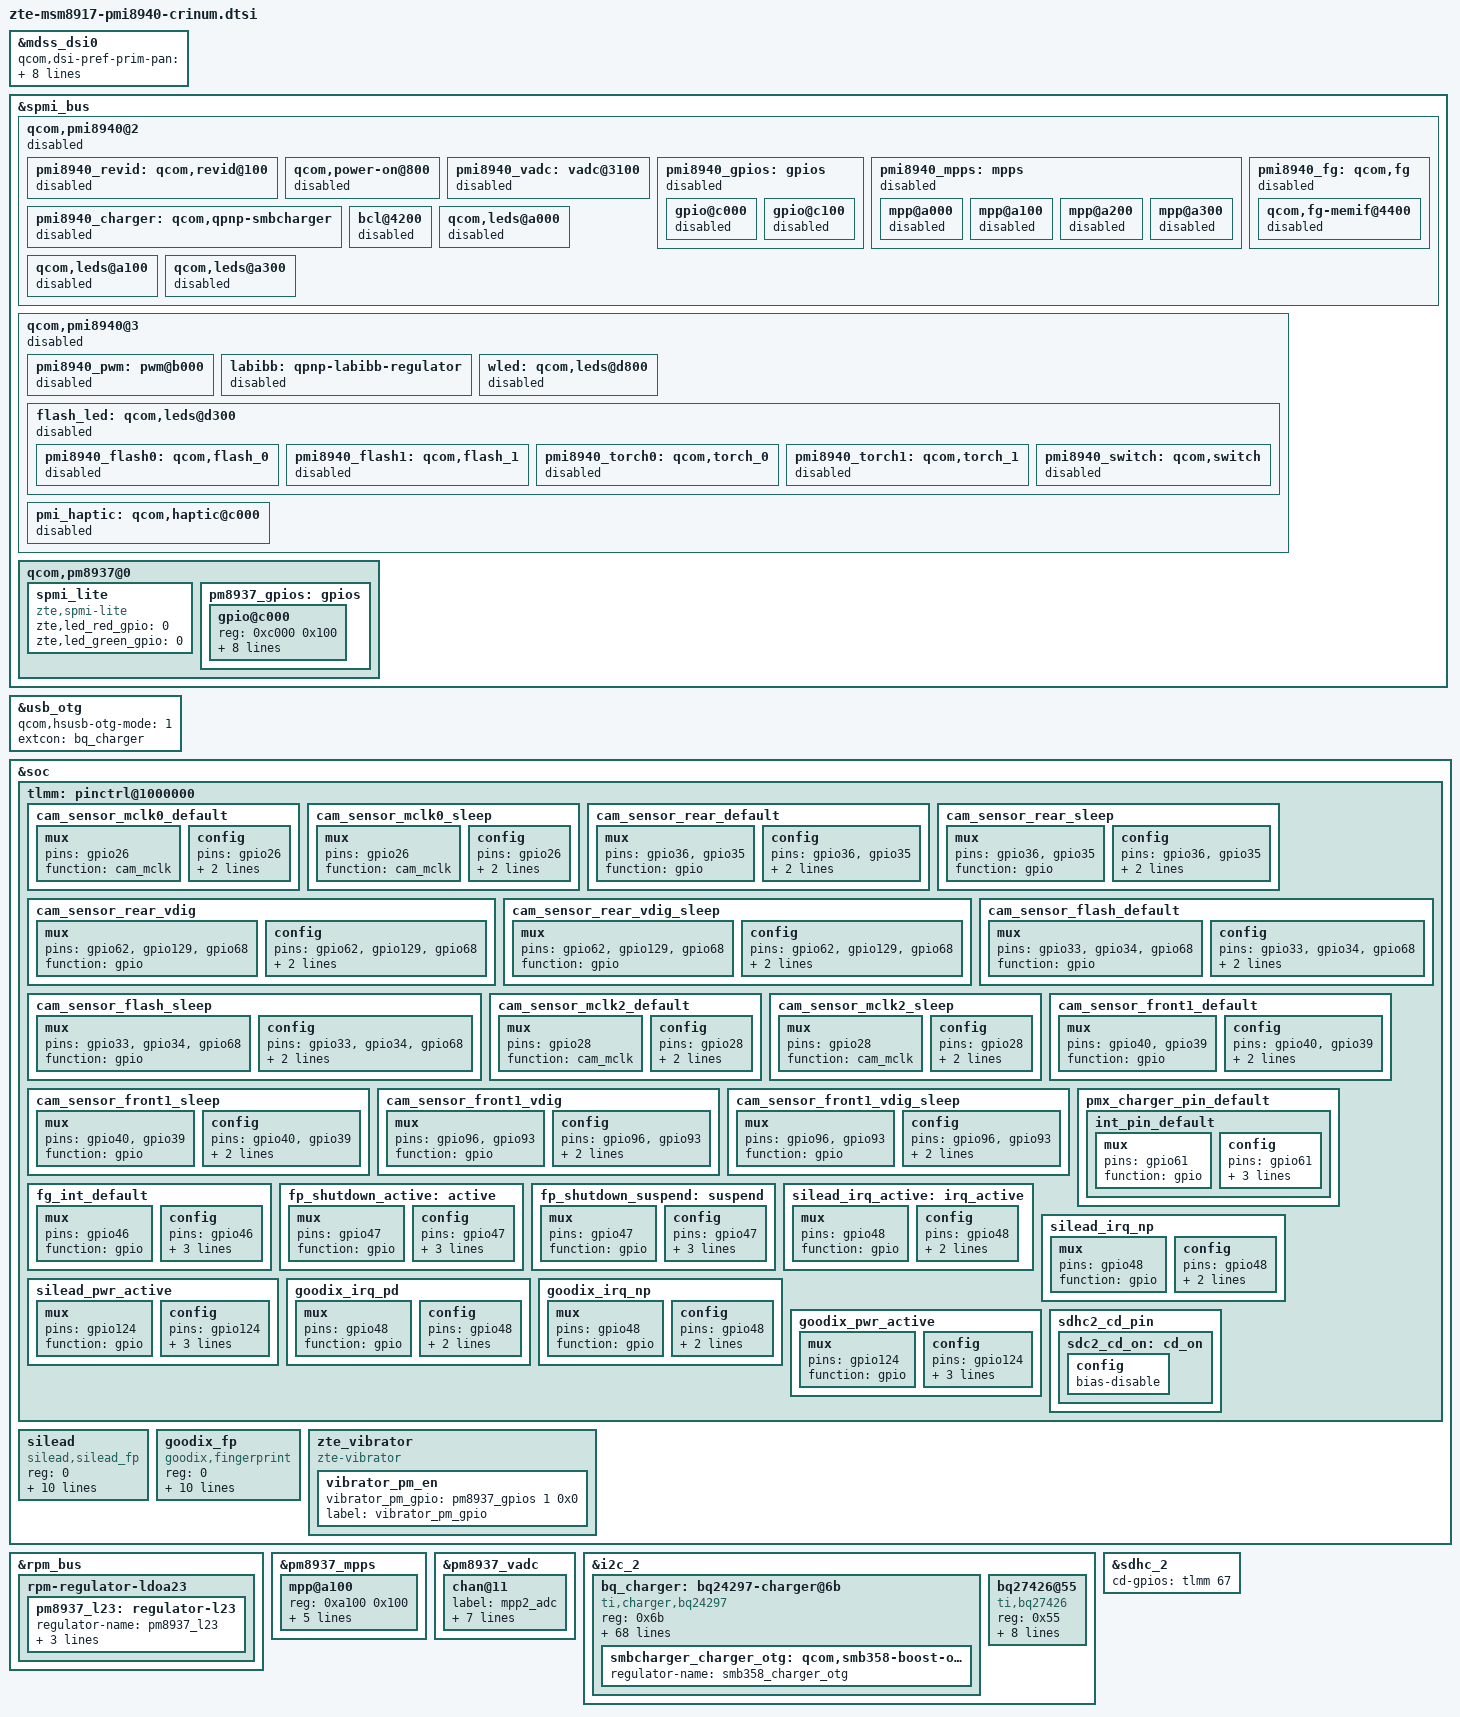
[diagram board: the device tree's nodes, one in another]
/*
 * Copyright (c) 2016, The Linux Foundation. All rights reserved.
 *
 * This program is free software; you can redistribute it and/or modify
 * it under the terms of the GNU General Public License version 2 and
 * only version 2 as published by the Free Software Foundation.
 *
 * This program is distributed in the hope that it will be useful,
 * but WITHOUT ANY WARRANTY; without even the implied warranty of
 * MERCHANTABILITY or FITNESS FOR A PARTICULAR PURPOSE.  See the
 * GNU General Public License for more details.
 */

/*
* device tree for zte crinum board
*/

#include "dsi-panel-zte-truly-otm1290a-cpt-5p5-720p-video.dtsi"
#include "dsi-panel-zte-lianchuang-jd9365d-hsd-720p-video.dtsi"
#include "dsi-panel-zte-helitai-st7703-hsd-5p5-720p-video.dtsi"

&mdss_dsi0 {
	qcom,dsi-pref-prim-pan = <&dsi_truly_otm1290a_cpt_720p_video>;
	pinctrl-names = "mdss_default", "mdss_sleep";
	pinctrl-0 = <&mdss_dsi_active &mdss_te_active>;
	pinctrl-1 = <&mdss_dsi_suspend &mdss_te_suspend>;

	qcom,platform-te-gpio = <&tlmm 24 0>;
	qcom,platform-reset-gpio = <&tlmm 60 0>;

	qcom,regulator-ldo-mode;

	zte,disp_vsp_en_gpio = <&tlmm 89 0>;
	zte,disp_vsn_en_gpio = <&tlmm 90 0>;
};

&spmi_bus {
	qcom,pmi8940@2 {
		status = "disabled";

		pmi8940_revid: qcom,revid@100 {
			status = "disabled";
		};

		qcom,power-on@800 {
			status = "disabled";
		};

		pmi8940_vadc: vadc@3100 {
			status = "disabled";
		};

		pmi8940_gpios: gpios {
			status = "disabled";

			gpio@c000 {
				status = "disabled";
			};

			gpio@c100 {
				status = "disabled";
			};
		};

		pmi8940_mpps: mpps {
			status = "disabled";

			mpp@a000 {
				status = "disabled";
			};

			mpp@a100 {
				status = "disabled";
			};

			mpp@a200 {
				status = "disabled";
			};

			mpp@a300 {
				status = "disabled";
			};
		};

		pmi8940_charger: qcom,qpnp-smbcharger {
			status = "disabled";
		};

		pmi8940_fg: qcom,fg {
			status = "disabled";

			qcom,fg-memif@4400 {
				status = "disabled";
			};
		};

		bcl@4200 {
			status = "disabled";
		};
		qcom,leds@a000 {
			status = "disabled";
		};
		qcom,leds@a100 {
			status = "disabled";
		};
		qcom,leds@a300 {
			status = "disabled";
		};
	};

	qcom,pmi8940@3 {
		status = "disabled";

		pmi8940_pwm: pwm@b000 {
			status = "disabled";
		};

		labibb: qpnp-labibb-regulator {
			status = "disabled";
		};

		wled: qcom,leds@d800 {
			status = "disabled";
		};

		flash_led: qcom,leds@d300 {
			status = "disabled";

			pmi8940_flash0: qcom,flash_0 {
				status = "disabled";
			};

			pmi8940_flash1: qcom,flash_1 {
				status = "disabled";
			};

			pmi8940_torch0: qcom,torch_0 {
				status = "disabled";
			};

			pmi8940_torch1: qcom,torch_1 {
				status = "disabled";
			};

			pmi8940_switch: qcom,switch {
				status = "disabled";
			};
		};

		pmi_haptic: qcom,haptic@c000 {
			status = "disabled";
		};
	};
};

&usb_otg {
	qcom,hsusb-otg-mode = <1>;
	extcon = <&bq_charger>;
};

/*ZTE yuxin add for zte Z5151V crinum prj camera gpios 2017.12.16 begin*/
&soc {
	tlmm: pinctrl@1000000 {
	/*sensors */
		cam_sensor_mclk0_default: cam_sensor_mclk0_default {
			/* MCLK0 */
				mux {
				/* CLK, DATA */
				pins = "gpio26";
				function = "cam_mclk";
			};

			config {
				pins = "gpio26";
				bias-disable; /* No PULL */
				drive-strength = <4>; /* 2 MA */
			};
		};

		cam_sensor_mclk0_sleep: cam_sensor_mclk0_sleep {
			/* MCLK0 */
			mux {
				/* CLK, DATA */
				pins = "gpio26";
				function = "cam_mclk";
			};

			config {
				pins = "gpio26";
				bias-pull-down; /* PULL DOWN */
				drive-strength = <4>; /* 2 MA */
			};
		};

		cam_sensor_rear_default: cam_sensor_rear_default {
			/* RESET, STANDBY */
			mux {
				pins = "gpio36", "gpio35";
				function = "gpio";
			};

			config {
				pins = "gpio36","gpio35";
				bias-disable; /* No PULL */
				drive-strength = <2>; /* 2 MA */
			};
		};

		cam_sensor_rear_sleep: cam_sensor_rear_sleep {
			/* RESET, STANDBY */
			mux {
				pins = "gpio36","gpio35";
				function = "gpio";
			};

			config {
				pins = "gpio36","gpio35";
				bias-disable; /* No PULL */
				drive-strength = <2>; /* 2 MA */
			};
		};

		cam_sensor_rear_vdig: cam_sensor_rear_vdig {
			/* VDIG */
			mux {
				pins = "gpio62","gpio129","gpio68";
				function = "gpio";
			};

			config {
				pins = "gpio62","gpio129","gpio68";
				bias-disable; /* No PULL */
				drive-strength = <2>; /* 2 MA */
			};
		};

		cam_sensor_rear_vdig_sleep: cam_sensor_rear_vdig_sleep {
			/* VDIG */
			mux {
				pins = "gpio62","gpio129","gpio68";
				function = "gpio";
			};

			config {
				pins = "gpio62","gpio129","gpio68";
				bias-disable; /* No PULL */
				drive-strength = <2>; /* 2 MA */
			};
		};
		/*yuxin add for Z5151V flash 20180123 ++*/
		cam_sensor_flash_default: cam_sensor_flash_default {
			/* VDIG */
			mux {
				pins = "gpio33", "gpio34", "gpio68";
				function = "gpio";
			};

			config {
				pins = "gpio33", "gpio34", "gpio68";
				bias-disable; /* No PULL */
				drive-strength = <2>; /* 2 MA */
			};
		};

		cam_sensor_flash_sleep: cam_sensor_flash_sleep {
			/* VDIG */
			mux {
				pins = "gpio33", "gpio34", "gpio68";
				function = "gpio";
			};

			config {
				pins = "gpio33", "gpio34", "gpio68";
				bias-disable; /* No PULL */
				drive-strength = <2>; /* 2 MA */
			};
		};
	/*yuxin add for Z5151V flash 20180123 --*/
		cam_sensor_mclk2_default: cam_sensor_mclk2_default {
			/* MCLK2 */
			mux {
				/* CLK, DATA */
				pins = "gpio28";
				function = "cam_mclk";
			};

			config {
				pins = "gpio28";
				bias-disable; /* No PULL */
				drive-strength = <4>; /* 2 MA */
			};
		};

		cam_sensor_mclk2_sleep: cam_sensor_mclk2_sleep {
			/* MCLK2 */
			mux {
				/* CLK, DATA */
				pins = "gpio28";
				function = "cam_mclk";
			};

			config {
				pins = "gpio28";
				bias-pull-down; /* PULL DOWN */
				drive-strength = <4>; /* 2 MA */
			};
		};

		cam_sensor_front1_default: cam_sensor_front1_default {
			/* RESET, STANDBY */
			mux {
				pins = "gpio40", "gpio39";
				function = "gpio";
			};

			config {
				pins = "gpio40", "gpio39";
				bias-disable; /* No PULL */
				drive-strength = <2>; /* 2 MA */
			};
		};

		cam_sensor_front1_sleep: cam_sensor_front1_sleep {
			/* RESET, STANDBY */
			mux {
				pins = "gpio40", "gpio39";
				function = "gpio";
			};

			config {
				pins = "gpio40", "gpio39";
				bias-disable; /* No PULL */
				drive-strength = <2>; /* 2 MA */
			};
		};
		cam_sensor_front1_vdig: cam_sensor_front1_vdig {
			/* VDIG */
			mux {
				pins = "gpio96", "gpio93"; /*"gpio68" is used for rear cam too*/
				function = "gpio";
			};

			config {
				pins = "gpio96", "gpio93"; /*"gpio68" is used for rear cam too*/
				bias-disable; /* No PULL */
				drive-strength = <2>; /* 2 MA */
			};
		};

		cam_sensor_front1_vdig_sleep: cam_sensor_front1_vdig_sleep {
			/* VDIG */
			mux {
				pins = "gpio96", "gpio93"; /*"gpio68" is used for rear cam too*/
				function = "gpio";
			};

			config {
				pins = "gpio96", "gpio93"; /*"gpio68" is used for rear cam too*/
				bias-disable; /* No PULL */
				drive-strength = <2>; /* 2 MA */
			};
		};

		pmx_charger_pin_default {
			int_pin_default: int_pin_default {
				mux {
					pins = "gpio61";
					function = "gpio";
				};

				config {
					pins = "gpio61";
					drive-strength = <2>;
					bias-disable;
					input-enable;
				};
			};
		};

		fg_int_default: fg_int_default {
			mux {
				pins = "gpio46";
				function = "gpio";
			};

			config {
				pins = "gpio46";
				drive-strength = <2>;
				bias-disable;
				input-enable;
			};
		};
	};
};
/*yuxin modify VREG_L23 voltage range for rear camera DVDD supply 20171222 begin*/
&rpm_bus {
	rpm-regulator-ldoa23 {
		status = "okay";
		pm8937_l23: regulator-l23 {
			regulator-name = "pm8937_l23";
			regulator-min-microvolt = <1050000>;
			regulator-max-microvolt = <1200000>;
			qcom,init-voltage = <1050000>;
			status = "okay";
		};
	};
};
/*yuxin modify VREG_L23 voltage range for rear camera DVDD supply 20171222 end*/

/*ZTE yuxin add for zte Z5151V crinum prj camera gpios 2017.12.16 end*/

&tlmm {
	fp_shutdown_active:active{
		mux{
			pins = "gpio47";
			function = "gpio";
		};
		config{
			pins = "gpio47";
			drive-strength = <6>;
			output-high;
			bias-disable = <0>;
		};
	};

	fp_shutdown_suspend:suspend{
		mux{
			pins = "gpio47";
			function = "gpio";
		};
		config{
			pins = "gpio47";
			drive-strength = <2>;
			output-low;
			bias-disable = <0>;
		};
	};

	silead_irq_active:irq_active{
		mux{
			pins = "gpio48";
			function = "gpio";
		};
		config{
			pins = "gpio48";
			drive-strength = <2>;
			bias-pull-down;
		};
	};
	silead_irq_np:silead_irq_np{
		mux{
			pins = "gpio48";
			function = "gpio";
		};
		config{
			pins = "gpio48";
			drive-strength = <2>;
			bias-disable; /* No PULL */
		};
	};

	silead_pwr_active: silead_pwr_active {
		mux{
			pins = "gpio124";
			function = "gpio";
		};
		config {
			pins = "gpio124";
			drive-strength = <2>;
			bias-disable;
			output-high;
		};
	};

	goodix_irq_pd: goodix_irq_pd{
		mux{
			pins = "gpio48";
			function = "gpio";
		};
		config{
			pins = "gpio48";
			drive-strength = <2>;
			bias-pull-down;
		};
	};
	goodix_irq_np: goodix_irq_np{
		mux{
			pins = "gpio48";
			function = "gpio";
		};
		config{
			pins = "gpio48";
			drive-strength = <2>;
			bias-disable; /* No PULL */
		};
	};
	goodix_pwr_active: goodix_pwr_active {
		mux{
			pins = "gpio124";
			function = "gpio";
		};
		config {
			pins = "gpio124";
			drive-strength = <2>;
			bias-disable;
			output-high;
		};
	};
};
&soc {
	/* zte for fingerprint */
	silead {
		status = "ok";
		reg = <0>;
		compatible = "silead,silead_fp";
		interrupt-parent = <&tlmm>;
		interrupts = <97 0x0>;

		pinctrl-names = "silead_active", "silead_suspend", "silead_irq", "pwr_active", "silead_irq_np";
		pinctrl-0 = <&fp_shutdown_active>;
		pinctrl-1 = <&fp_shutdown_suspend>;
		pinctrl-2 = <&silead_irq_active>;
		pinctrl-3 = <&silead_pwr_active>;
		pinctrl-4 = <&silead_irq_np>;

		silead,gpio_reset = <&tlmm 47 0>;
		silead,gpio_irq = <&tlmm 48 0>;
		silead,gpio_pwr = <&tlmm 124 0>;
		interrupt-names = "sl_wake_up";
	};

	goodix_fp {
		status = "ok";
		reg = <0>;
		compatible = "goodix,fingerprint";
		interrupt-parent = <&tlmm>;
		interrupts = <48 0x0>;

		pinctrl-names = "goodix_active", "goodix_suspend", "goodix_irq_pd", "goodix_irq_np", "pwr_active";
		pinctrl-0 = <&fp_shutdown_active>;
		pinctrl-1 = <&fp_shutdown_suspend>;
		pinctrl-2 = <&goodix_irq_pd>;
		pinctrl-3 = <&goodix_irq_np>;
		pinctrl-4 = <&goodix_pwr_active>;

		fp-gpio-reset = <&tlmm 47 0>;
		fp-gpio-irq = <&tlmm 48 0>;
		fp-gpio-pwr = <&tlmm 124 0>;
		interrupt-names = "goodix_wake_up";
	};

	zte_vibrator {
		compatible = "zte-vibrator";
		vibrator_pm_en{
			vibrator_pm_gpio = <&pm8937_gpios 1 0x0>;
			label = "vibrator_pm_gpio";
		};
	};
};

&pm8937_mpps {
		mpp@a100 {
		/* MPP2 - BATT_ID config */
		reg = <0xa100 0x100>;
		qcom,pin-num = <2>;
		qcom,mode = <4>; /* AIN input */
		qcom,ain-route = <1>; /* AMUX 6 */
		qcom,master-en = <1>;
		qcom,src-sel = <0>; /* Function constant */
		/delete-property/qcom,invert;
		};
};

&pm8937_vadc {
		chan@11 {
		label = "mpp2_adc";
		reg = <0x11>;
		qcom,decimation = <0>;
		qcom,pre-div-channel-scaling = <0>;
		qcom,calibration-type = "absolute";
		qcom,scale-function = <0>;
		qcom,hw-settle-time = <1>;
		qcom,fast-avg-setup = <2>;
		/delete-property/qcom,vadc-thermal-node;
	};
};

&i2c_2 {
	status = "ok";
	bq_charger: bq24297-charger@6b {
		compatible = "ti,charger,bq24297";
		reg = <0x6b>;
		interrupt-parent = <&tlmm>;
		interrupts = <61 0x0>;

		pinctrl-names = "default";
		pinctrl-0 = <&int_pin_default>;

		/* ti,irq-gpio = <&tlmm 63 0x00>; */

		ti,bq2429x,usb-vlim = <4520>;
		ti,bq2429x,usb-ilim = <512>;
		ti,bq2429x,usb-float-voltage-mv = <4400>;
		ti,bq2429x,usb-ichg = <512>;

		ti,bq2429x,cdp-vlim = <4520>;
		ti,bq2429x,cdp-ilim = <1500>;
		ti,bq2429x,cdp-ichg = <1216>;
		ti,bq2429x,cdp-float-voltage-mv = <4352>;

		ti,bq2429x,ta-vlim = <4520>;
		ti,bq2429x,ta-ilim = <2000>;
		ti,bq2429x,ta-ichg = <2048>;
		ti,bq2429x,ta-float-voltage-mv = <4400>;

		ti,recharge-mv = <300>;

		ti,bq2429x,software-jeita-supported;
		ti,bq2429x,jeita-hot-degc = <600>;
		ti,bq2429x,jeita-warm-degc = <450>;
		ti,bq2429x,jeita-cool-degc = <150>;
		ti,bq2429x,jeita-cold-degc = <0>;
		ti,bq2429x,jeita-cool-ma = <600>;
		ti,bq2429x,jeita-cool-mv = <4400>;
		ti,bq2429x,jeita-warm-ma = <600>;
		ti,bq2429x,jeita-warm-mv = <4100>;
		ti,bq2429x,jeita-cold-hysteresis = <20>;
		ti,bq2429x,jeita-hot-hysteresis = <20>;
		ti,bq2429x,thermal-mitigation = <2048 1408 1024 640>;

		ti,bq2429x,precharge-current = <384>;
		ti,bq2429x,termination-current = <128>;
		ti,bq2429x,boost-volt = <4998>;
		ti,bq2429x,boost-current = <1000>;
		/* ti,bq2429x,enable_term; */

		/* --------------------------fot ti bq25601 compatible--------------------------------------- */
		/* ti,charge_enable-gpio = <&tlmm 8 0x00>; */
		/* light add note:*/
		/* ichg:battery charging current */
		/* vreg:battery float voltage */
		/* ilim:charging input current */
		/* vlim:input voltage */

		ti,bq2560x,usb-vlim = <4520>;
		ti,bq2560x,usb-ilim = <500>;
		ti,bq2560x,usb-vreg = <4400>;
		ti,bq2560x,usb-ichg = <500>;

		ti,bq2560x,cdp-vlim = <4520>;
		ti,bq2560x,cdp-ilim = <1500>;
		ti,bq2560x,cdp-vreg = <4400>;
		ti,bq2560x,cdp-ichg = <2000>;

		ti,bq2560x,ta-vlim = <4520>;
		ti,bq2560x,ta-ilim = <1500>;
		ti,bq2560x,ta-vreg = <4400>;
		ti,bq2560x,ta-ichg = <2000>;

		ti,bq2560x,precharge-current = <384>;
		ti,bq2560x,termination-current = <128>;
		ti,bq2560x,boost-voltage = <4998>;
		ti,bq2560x,boost-current = <1200>;

		ti,bq2560x,stat-pin-ctrl = <0>;
		ti,bq2560x,vac-ovp-threshold = <6200>;

		ti,bq2560x,jeita-hot-degc = <550>;
		ti,bq2560x,jeita-warm-degc = <450>;
		ti,bq2560x,jeita-cool-degc = <100>;
		ti,bq2560x,jeita-cooler-degc = <50>;
		ti,bq2560x,jeita-cold-degc = <10>;

		ti,bq2560x,jeita-hot-hysteresis = <50>;
		ti,bq2560x,jeita-cold-hysteresis = <20>;

		ti,bq2560x,jeita-cooler-ma = <300>;
		ti,bq2560x,jeita-cool-ma = <900>;
		ti,bq2560x,jeita-cool-mv = <4400>;
		ti,bq2560x,jeita-warm-ma = <1000>;
		ti,bq2560x,jeita-warm-mv = <4100>;

		ti,bq2560x,recharge-mv = <100>;

		ti,bq2560x,enable_term;
		/*ti,bq2560x,enable_soc_term_charge;*/
		ti,bq2560x,software-jeita-supported;
		ti,bq2560x,thermal-mitigation = <1500 1000 700 500>;
		smbcharger_charger_otg: qcom,smb358-boost-otg {
				regulator-name = "smb358_charger_otg";
		};
	};

	bq27426@55 {
		compatible = "ti,bq27426";
		reg = <0x55>;
		interrupt-parent = <&tlmm>;
		interrupts = <46 2>;
		pinctrl-names = "default";
		pinctrl-0 = <&fg_int_default>;
		qcom,irq-gpio = <&tlmm 46 0x0>;
		qcom,batt_id-vadc = <&pm8937_vadc>;
		qcom,batt-id-vref-uv = <1800000>;
		qcom,batt-id-rpullup-kohm = <10>;
		qcom,batt_full_design_capacity = <3100>;
	};
};

&spmi_bus {
	qcom,pm8937@0 {
		spmi_lite {
			compatible = "zte,spmi-lite";
			zte,led_red_gpio = <0>;
			zte,led_green_gpio = <0>;
		};

		pm8937_gpios: gpios {
			gpio@c000 {
				reg = <0xc000 0x100>;
				qcom,pin-num = <1>;
				qcom,mode = <0>;
				qcom,output-type = <0>;
				qcom,pull = <0>;
				qcom,vin-sel = <3>;
				qcom,out-strength = <3>;
				qcom,src-sel = <0>;
				qcom,master-en = <0>;
				//qcom,dtest-sel = <1>;
				status = "okay";
			};
		};
	};
};

&sdhc_2 {
	cd-gpios = <&tlmm 67 0x0>;
};
&soc {
	tlmm: pinctrl@1000000 {
		sdhc2_cd_pin {
			sdc2_cd_on: cd_on {
				config {
					/delete-property/bias-pull-up;
					bias-disable;
				};
			};
		};
	};
};
